VERSION ""

NS_ :

BS_:

BU_:

BO_ 3221225472 VECTOR__INDEPENDENT_SIG_MSG: 0 Vector__XXX
 SG_ New_Signal_100 : 0|8@1- (1,0) [0|0] "" Vector__XXX

BO_ 352 Shutdown_seq: 8 Vector__XXX
 SG_ shutdown_2 : 63|8@0+ (1,0) [0|0] "" Vector__XXX
 SG_ shutdown : 55|8@0+ (1,0) [0|0] "" Vector__XXX

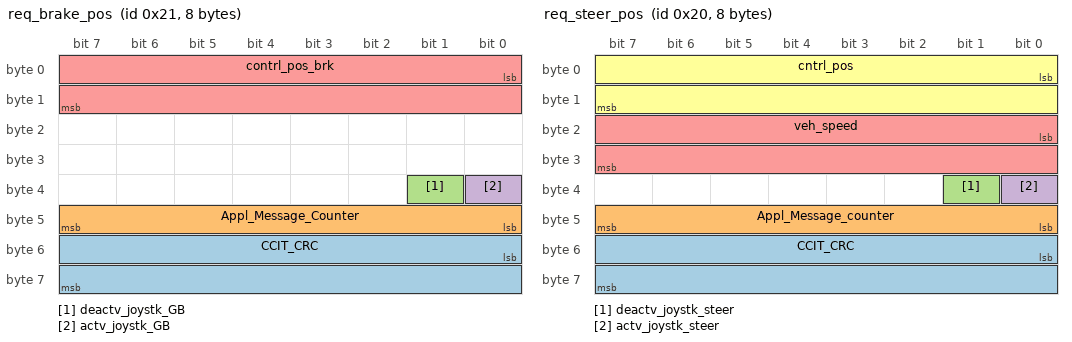
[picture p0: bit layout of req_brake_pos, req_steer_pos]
BO_ 33 req_brake_pos: 8 Vector__XXX
 SG_ CCIT_CRC : 48|16@1+ (1,0) [0|65535] "" Vector__XXX
 SG_ Appl_Message_Counter : 40|8@1+ (1,0) [0|255] "" Vector__XXX
 SG_ deactv_joystk_GB : 33|1@1+ (1,0) [0|1] "" Vector__XXX
 SG_ actv_joystk_GB : 32|1@1+ (1,0) [0|1] "" Vector__XXX
 SG_ contrl_pos_brk : 0|16@1+ (1,0) [0|65535] "" Vector__XXX

BO_ 32 req_steer_pos: 8 Vector__XXX
 SG_ CCIT_CRC : 48|16@1+ (1,0) [0|65535] "" Vector__XXX
 SG_ Appl_Message_counter : 40|8@1+ (1,0) [0|255] "" Vector__XXX
 SG_ deactv_joystk_steer : 33|1@1+ (1,0) [0|1] "" Vector__XXX
 SG_ actv_joystk_steer : 32|1@1+ (1,0) [0|1] "" Vector__XXX
 SG_ veh_speed : 16|16@1+ (1,0) [0|65535] "" Vector__XXX
 SG_ cntrl_pos : 0|16@1+ (1,0) [0|65535] "" Vector__XXX

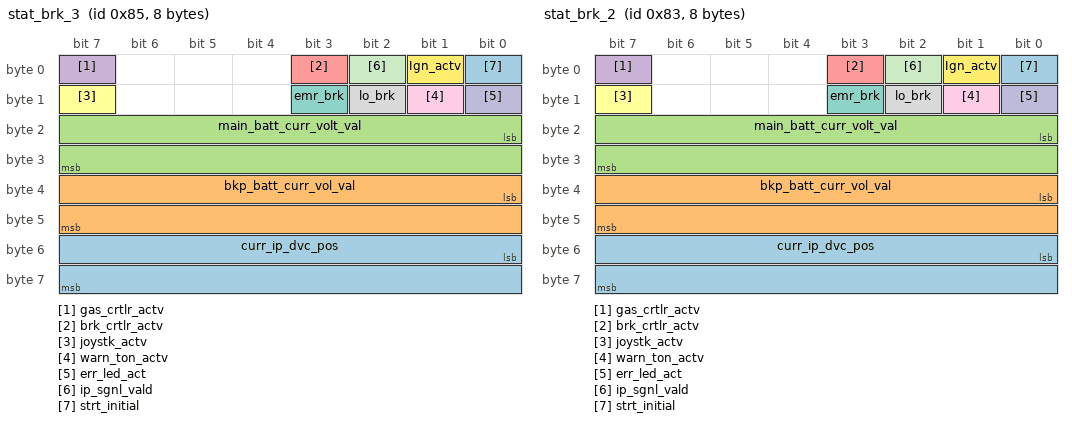
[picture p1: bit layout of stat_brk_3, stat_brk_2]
BO_ 133 stat_brk_3: 8 Vector__XXX
 SG_ curr_ip_dvc_pos : 48|16@1+ (1,0) [0|65535] "" Vector__XXX
 SG_ bkp_batt_curr_vol_val : 32|16@1+ (1,0) [0|65535] "" Vector__XXX
 SG_ main_batt_curr_volt_val : 16|16@1+ (1,0) [0|65535] "" Vector__XXX
 SG_ gas_crtlr_actv : 7|1@1+ (1,0) [0|1] "" Vector__XXX
 SG_ brk_crtlr_actv : 3|1@1+ (1,0) [0|1] "" Vector__XXX
 SG_ joystk_actv : 15|1@1+ (1,0) [0|1] "" Vector__XXX
 SG_ emr_brk : 11|1@1+ (1,0) [0|1] "" Vector__XXX
 SG_ lo_brk : 10|1@1+ (1,0) [0|1] "" Vector__XXX
 SG_ warn_ton_actv : 9|1@1+ (1,0) [0|1] "" Vector__XXX
 SG_ err_led_act : 8|1@1+ (1,0) [0|1] "" Vector__XXX
 SG_ ip_sgnl_vald : 2|1@1+ (1,0) [0|1] "" Vector__XXX
 SG_ Ign_actv : 1|1@1+ (1,0) [0|1] "" Vector__XXX
 SG_ strt_initial : 0|1@1+ (1,0) [0|1] "" Vector__XXX

BO_ 131 stat_brk_2: 8 Vector__XXX
 SG_ curr_ip_dvc_pos : 48|16@1+ (1,0) [0|65535] "" Vector__XXX
 SG_ bkp_batt_curr_vol_val : 32|16@1+ (1,0) [0|65535] "" Vector__XXX
 SG_ main_batt_curr_volt_val : 16|16@1+ (1,0) [0|65535] "" Vector__XXX
 SG_ gas_crtlr_actv : 7|1@1+ (1,0) [0|1] "" Vector__XXX
 SG_ brk_crtlr_actv : 3|1@1+ (1,0) [0|1] "" Vector__XXX
 SG_ joystk_actv : 15|1@1+ (1,0) [0|1] "" Vector__XXX
 SG_ emr_brk : 11|1@1+ (1,0) [0|1] "" Vector__XXX
 SG_ lo_brk : 10|1@1+ (1,0) [0|1] "" Vector__XXX
 SG_ warn_ton_actv : 9|1@1+ (1,0) [0|1] "" Vector__XXX
 SG_ err_led_act : 8|1@1+ (1,0) [0|1] "" Vector__XXX
 SG_ ip_sgnl_vald : 2|1@1+ (1,0) [0|1] "" Vector__XXX
 SG_ Ign_actv : 1|1@1+ (1,0) [0|1] "" Vector__XXX
 SG_ strt_initial : 0|1@1+ (1,0) [0|1] "" Vector__XXX

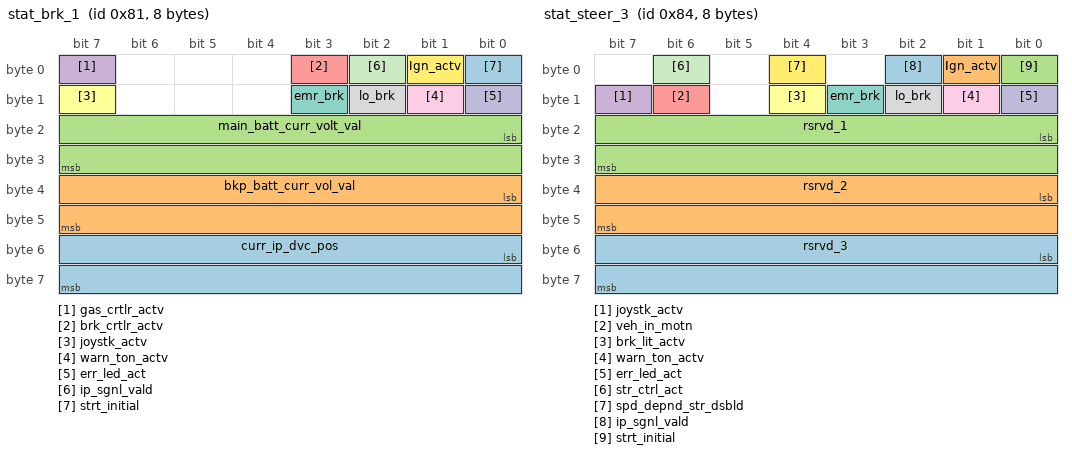
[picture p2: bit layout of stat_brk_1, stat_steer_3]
BO_ 129 stat_brk_1: 8 Vector__XXX
 SG_ curr_ip_dvc_pos : 48|16@1+ (1,0) [0|65535] "" Vector__XXX
 SG_ bkp_batt_curr_vol_val : 32|16@1+ (1,0) [0|65535] "" Vector__XXX
 SG_ main_batt_curr_volt_val : 16|16@1+ (1,0) [0|65535] "" Vector__XXX
 SG_ gas_crtlr_actv : 7|1@1+ (1,0) [0|1] "" Vector__XXX
 SG_ brk_crtlr_actv : 3|1@1+ (1,0) [0|1] "" Vector__XXX
 SG_ joystk_actv : 15|1@1+ (1,0) [0|1] "" Vector__XXX
 SG_ emr_brk : 11|1@1+ (1,0) [0|1] "" Vector__XXX
 SG_ lo_brk : 10|1@1+ (1,0) [0|1] "" Vector__XXX
 SG_ warn_ton_actv : 9|1@1+ (1,0) [0|1] "" Vector__XXX
 SG_ err_led_act : 8|1@1+ (1,0) [0|1] "" Vector__XXX
 SG_ ip_sgnl_vald : 2|1@1+ (1,0) [0|1] "" Vector__XXX
 SG_ Ign_actv : 1|1@1+ (1,0) [0|1] "" Vector__XXX
 SG_ strt_initial : 0|1@1+ (1,0) [0|1] "" Vector__XXX

BO_ 132 stat_steer_3: 8 Vector__XXX
 SG_ rsrvd_3 : 48|16@1+ (1,0) [0|65535] "" Vector__XXX
 SG_ rsrvd_2 : 32|16@1+ (1,0) [0|65535] "" Vector__XXX
 SG_ rsrvd_1 : 16|16@1+ (1,0) [0|65535] "" Vector__XXX
 SG_ joystk_actv : 15|1@1+ (1,0) [0|1] "" Vector__XXX
 SG_ veh_in_motn : 14|1@1+ (1,0) [0|1] "" Vector__XXX
 SG_ brk_lit_actv : 12|1@1+ (1,0) [0|1] "" Vector__XXX
 SG_ emr_brk : 11|1@1+ (1,0) [0|1] "" Vector__XXX
 SG_ lo_brk : 10|1@1+ (1,0) [0|1] "" Vector__XXX
 SG_ warn_ton_actv : 9|1@1+ (1,0) [0|1] "" Vector__XXX
 SG_ err_led_act : 8|1@1+ (1,0) [0|1] "" Vector__XXX
 SG_ str_ctrl_act : 6|1@1+ (1,0) [0|1] "" Vector__XXX
 SG_ spd_depnd_str_dsbld : 4|1@1+ (1,0) [0|1] "" Vector__XXX
 SG_ ip_sgnl_vald : 2|1@1+ (1,0) [0|1] "" Vector__XXX
 SG_ Ign_actv : 1|1@1+ (1,0) [0|1] "" Vector__XXX
 SG_ strt_initial : 0|1@1+ (1,0) [0|1] "" Vector__XXX

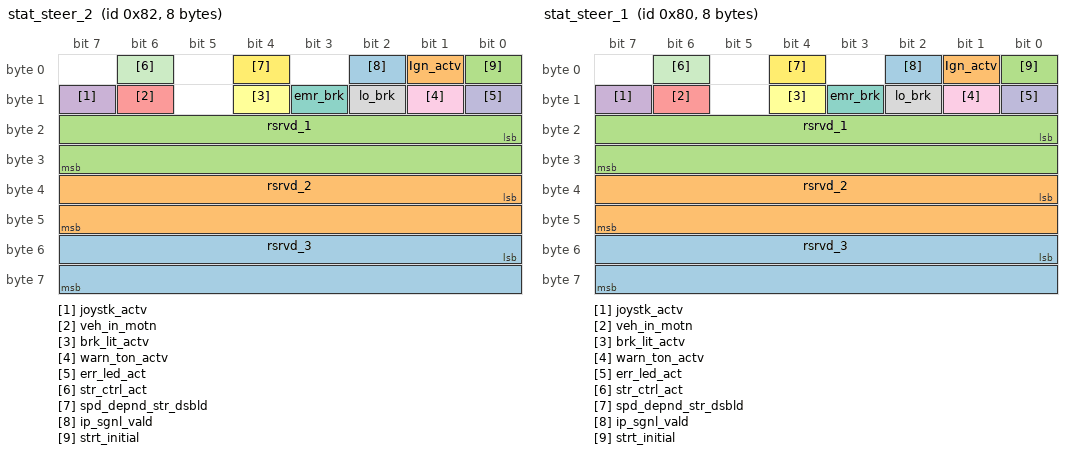
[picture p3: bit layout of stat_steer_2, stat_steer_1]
BO_ 130 stat_steer_2: 8 Vector__XXX
 SG_ rsrvd_3 : 48|16@1+ (1,0) [0|65535] "" Vector__XXX
 SG_ rsrvd_2 : 32|16@1+ (1,0) [0|65535] "" Vector__XXX
 SG_ rsrvd_1 : 16|16@1+ (1,0) [0|65535] "" Vector__XXX
 SG_ joystk_actv : 15|1@1+ (1,0) [0|1] "" Vector__XXX
 SG_ veh_in_motn : 14|1@1+ (1,0) [0|1] "" Vector__XXX
 SG_ brk_lit_actv : 12|1@1+ (1,0) [0|1] "" Vector__XXX
 SG_ emr_brk : 11|1@1+ (1,0) [0|1] "" Vector__XXX
 SG_ lo_brk : 10|1@1+ (1,0) [0|1] "" Vector__XXX
 SG_ warn_ton_actv : 9|1@1+ (1,0) [0|1] "" Vector__XXX
 SG_ err_led_act : 8|1@1+ (1,0) [0|1] "" Vector__XXX
 SG_ str_ctrl_act : 6|1@1+ (1,0) [0|1] "" Vector__XXX
 SG_ spd_depnd_str_dsbld : 4|1@1+ (1,0) [0|1] "" Vector__XXX
 SG_ ip_sgnl_vald : 2|1@1+ (1,0) [0|1] "" Vector__XXX
 SG_ Ign_actv : 1|1@1+ (1,0) [0|1] "" Vector__XXX
 SG_ strt_initial : 0|1@1+ (1,0) [0|1] "" Vector__XXX

BO_ 128 stat_steer_1: 8 Vector__XXX
 SG_ rsrvd_3 : 48|16@1+ (1,0) [0|65535] "" Vector__XXX
 SG_ rsrvd_2 : 32|16@1+ (1,0) [0|65535] "" Vector__XXX
 SG_ rsrvd_1 : 16|16@1+ (1,0) [0|65535] "" Vector__XXX
 SG_ joystk_actv : 15|1@1+ (1,0) [0|1] "" Vector__XXX
 SG_ veh_in_motn : 14|1@1+ (1,0) [0|1] "" Vector__XXX
 SG_ brk_lit_actv : 12|1@1+ (1,0) [0|1] "" Vector__XXX
 SG_ emr_brk : 11|1@1+ (1,0) [0|1] "" Vector__XXX
 SG_ lo_brk : 10|1@1+ (1,0) [0|1] "" Vector__XXX
 SG_ warn_ton_actv : 9|1@1+ (1,0) [0|1] "" Vector__XXX
 SG_ err_led_act : 8|1@1+ (1,0) [0|1] "" Vector__XXX
 SG_ str_ctrl_act : 6|1@1+ (1,0) [0|1] "" Vector__XXX
 SG_ spd_depnd_str_dsbld : 4|1@1+ (1,0) [0|1] "" Vector__XXX
 SG_ ip_sgnl_vald : 2|1@1+ (1,0) [0|1] "" Vector__XXX
 SG_ Ign_actv : 1|1@1+ (1,0) [0|1] "" Vector__XXX
 SG_ strt_initial : 0|1@1+ (1,0) [0|1] "" Vector__XXX

BO_ 101 act_err_brake_3: 8 Vector__XXX
 SG_ crtcl_err_recognzd : 62|1@1+ (1,0) [0|1] "" Vector__XXX
 SG_ err_CAN_2 : 58|1@1+ (1,0) [0|1] "" Vector__XXX
 SG_ err_CAN_1 : 57|1@1+ (1,0) [0|1] "" Vector__XXX
 SG_ ovrld_mtr_pwr : 51|1@1+ (1,0) [0|1] "" Vector__XXX
 SG_ runtm_err : 50|1@1+ (1,0) [0|1] "" Vector__XXX
 SG_ err_memo_100_pcnt_full : 44|1@1+ (1,0) [0|1] "" Vector__XXX
 SG_ err_memo_80_pcnt_full : 43|1@1+ (1,0) [0|1] "" Vector__XXX
 SG_ ctrlr_temp_to_hi : 42|1@1+ (1,0) [0|1] "" Vector__XXX
 SG_ psn_sen_srv_mtr_implausible : 39|1@1+ (1,0) [0|1] "" Vector__XXX
 SG_ RESET_whl_optg : 38|1@1+ (1,0) [0|1] "" Vector__XXX
 SG_ err_ctrl_val_2 : 37|1@1+ (1,0) [0|1] "" Vector__XXX
 SG_ err_ctrl_val_1 : 36|1@1+ (1,0) [0|1] "" Vector__XXX
 SG_ err_ngv_voltg_pwr_supp_3 : 35|1@1+ (1,0) [0|1] "" Vector__XXX
 SG_ err_ngv_voltg_pwr_supp_2 : 34|1@1+ (1,0) [0|1] "" Vector__XXX
 SG_ err_ngv_voltg_pwr_supp_1 : 33|1@1+ (1,0) [0|1] "" Vector__XXX
 SG_ err_3p3V_pwr_supp_2 : 32|1@1+ (1,0) [0|1] "" Vector__XXX
 SG_ err_3p3V_pwr_supp_1 : 31|1@1+ (1,0) [0|1] "" Vector__XXX
 SG_ err_5V_pwr_supp_3 : 30|1@1+ (1,0) [0|1] "" Vector__XXX
 SG_ err_5V_pwr_supp_2 : 29|1@1+ (1,0) [0|1] "" Vector__XXX
 SG_ err_5V_pwr_supp_1 : 28|1@1+ (1,0) [0|1] "" Vector__XXX
 SG_ H_brdg_3_fail : 27|1@1+ (1,0) [0|1] "" Vector__XXX
 SG_ H_brdg_2_fail : 26|1@1+ (1,0) [0|1] "" Vector__XXX
 SG_ H_brdg_1_fail : 25|1@1+ (1,0) [0|1] "" Vector__XXX
 SG_ err_srv_mtr_pos_sen_3 : 23|1@1+ (1,0) [0|1] "" Vector__XXX
 SG_ err_srv_mtr_2_STR_pwr_drn : 22|1@1+ (1,0) [0|1] "" Vector__XXX
 SG_ err_srv_mtr_1_STR_pwr_drn : 21|1@1+ (1,0) [0|1] "" Vector__XXX
 SG_ RAM_Chk_fail : 20|1@1+ (1,0) [0|1] "" Vector__XXX
 SG_ flsh_CRC_fail : 19|1@1+ (1,0) [0|1] "" Vector__XXX
 SG_ Ctrlr_temp_crit_low : 12|1@1+ (1,0) [0|1] "" Vector__XXX
 SG_ Ctrlr_temp_crit_hi : 11|1@1+ (1,0) [0|1] "" Vector__XXX
 SG_ err_srv_mtr_2_GB_pwr_drn : 10|1@1+ (1,0) [0|1] "" Vector__XXX
 SG_ err_srv_mtr_1_GB_pwr_drn : 9|1@1+ (1,0) [0|1] "" Vector__XXX
 SG_ Vol_bkp_batt_lo : 8|1@1+ (1,0) [0|1] "" Vector__XXX
 SG_ Vol_bkp_batt_hi : 7|1@1+ (1,0) [0|1] "" Vector__XXX
 SG_ Vol_main_batt_lo : 6|1@1+ (1,0) [0|1] "" Vector__XXX
 SG_ Vol_main_batt_hi : 5|1@1+ (1,0) [0|1] "" Vector__XXX
 SG_ err_srv_mtr_pos_sen_2 : 4|1@1+ (1,0) [0|1] "" Vector__XXX
 SG_ err_srv_mtr_pos_sen_1 : 3|1@1+ (1,0) [0|1] "" Vector__XXX
 SG_ ip_dvc_err_sen_3 : 2|1@1+ (1,0) [0|1] "" Vector__XXX
 SG_ ip_dvc_err_sen_2 : 1|1@1+ (1,0) [0|1] "" Vector__XXX
 SG_ ip_dvc_err_sen_1 : 0|1@1+ (1,0) [0|1] "" Vector__XXX

BO_ 99 act_err_brake_2: 8 Vector__XXX
 SG_ crtcl_err_recognzd : 62|1@1+ (1,0) [0|1] "" Vector__XXX
 SG_ err_CAN_2 : 58|1@1+ (1,0) [0|1] "" Vector__XXX
 SG_ err_CAN_1 : 57|1@1+ (1,0) [0|1] "" Vector__XXX
 SG_ ovrld_mtr_pwr : 51|1@1+ (1,0) [0|1] "" Vector__XXX
 SG_ runtm_err : 50|1@1+ (1,0) [0|1] "" Vector__XXX
 SG_ err_memo_100_pcnt_full : 44|1@1+ (1,0) [0|1] "" Vector__XXX
 SG_ err_memo_80_pcnt_full : 43|1@1+ (1,0) [0|1] "" Vector__XXX
 SG_ ctrlr_temp_to_hi : 42|1@1+ (1,0) [0|1] "" Vector__XXX
 SG_ psn_sen_srv_mtr_implausible : 39|1@1+ (1,0) [0|1] "" Vector__XXX
 SG_ RESET_whl_optg : 38|1@1+ (1,0) [0|1] "" Vector__XXX
 SG_ err_ctrl_val_2 : 37|1@1+ (1,0) [0|1] "" Vector__XXX
 SG_ err_ctrl_val_1 : 36|1@1+ (1,0) [0|1] "" Vector__XXX
 SG_ err_ngv_voltg_pwr_supp_3 : 35|1@1+ (1,0) [0|1] "" Vector__XXX
 SG_ err_ngv_voltg_pwr_supp_2 : 34|1@1+ (1,0) [0|1] "" Vector__XXX
 SG_ err_ngv_voltg_pwr_supp_1 : 33|1@1+ (1,0) [0|1] "" Vector__XXX
 SG_ err_3p3V_pwr_supp_2 : 32|1@1+ (1,0) [0|1] "" Vector__XXX
 SG_ err_3p3V_pwr_supp_1 : 31|1@1+ (1,0) [0|1] "" Vector__XXX
 SG_ err_5V_pwr_supp_3 : 30|1@1+ (1,0) [0|1] "" Vector__XXX
 SG_ err_5V_pwr_supp_2 : 29|1@1+ (1,0) [0|1] "" Vector__XXX
 SG_ err_5V_pwr_supp_1 : 28|1@1+ (1,0) [0|1] "" Vector__XXX
 SG_ H_brdg_3_fail : 27|1@1+ (1,0) [0|1] "" Vector__XXX
 SG_ H_brdg_2_fail : 26|1@1+ (1,0) [0|1] "" Vector__XXX
 SG_ H_brdg_1_fail : 25|1@1+ (1,0) [0|1] "" Vector__XXX
 SG_ err_srv_mtr_pos_sen_3 : 23|1@1+ (1,0) [0|1] "" Vector__XXX
 SG_ err_srv_mtr_2_STR_pwr_drn : 22|1@1+ (1,0) [0|1] "" Vector__XXX
 SG_ err_srv_mtr_1_STR_pwr_drn : 21|1@1+ (1,0) [0|1] "" Vector__XXX
 SG_ RAM_Chk_fail : 20|1@1+ (1,0) [0|1] "" Vector__XXX
 SG_ flsh_CRC_fail : 19|1@1+ (1,0) [0|1] "" Vector__XXX
 SG_ Ctrlr_temp_crit_low : 12|1@1+ (1,0) [0|1] "" Vector__XXX
 SG_ Ctrlr_temp_crit_hi : 11|1@1+ (1,0) [0|1] "" Vector__XXX
 SG_ err_srv_mtr_2_GB_pwr_drn : 10|1@1+ (1,0) [0|1] "" Vector__XXX
 SG_ err_srv_mtr_1_GB_pwr_drn : 9|1@1+ (1,0) [0|1] "" Vector__XXX
 SG_ Vol_bkp_batt_lo : 8|1@1+ (1,0) [0|1] "" Vector__XXX
 SG_ Vol_bkp_batt_hi : 7|1@1+ (1,0) [0|1] "" Vector__XXX
 SG_ Vol_main_batt_lo : 6|1@1+ (1,0) [0|1] "" Vector__XXX
 SG_ Vol_main_batt_hi : 5|1@1+ (1,0) [0|1] "" Vector__XXX
 SG_ err_srv_mtr_pos_sen_2 : 4|1@1+ (1,0) [0|1] "" Vector__XXX
 SG_ err_srv_mtr_pos_sen_1 : 3|1@1+ (1,0) [0|1] "" Vector__XXX
 SG_ ip_dvc_err_sen_3 : 2|1@1+ (1,0) [0|1] "" Vector__XXX
 SG_ ip_dvc_err_sen_2 : 1|1@1+ (1,0) [0|1] "" Vector__XXX
 SG_ ip_dvc_err_sen_1 : 0|1@1+ (1,0) [0|1] "" Vector__XXX

BO_ 100 act_err_steer_3: 8 Vector__XXX
 SG_ crtcl_err_recognzd : 62|1@1+ (1,0) [0|1] "" Vector__XXX
 SG_ err_CAN_2 : 58|1@1+ (1,0) [0|1] "" Vector__XXX
 SG_ err_CAN_1 : 57|1@1+ (1,0) [0|1] "" Vector__XXX
 SG_ ovrld_mtr_pwr : 51|1@1+ (1,0) [0|1] "" Vector__XXX
 SG_ runtm_err : 50|1@1+ (1,0) [0|1] "" Vector__XXX
 SG_ err_memo_100_pcnt_full : 44|1@1+ (1,0) [0|1] "" Vector__XXX
 SG_ err_memo_80_pcnt_full : 43|1@1+ (1,0) [0|1] "" Vector__XXX
 SG_ ctrlr_temp_to_hi : 42|1@1+ (1,0) [0|1] "" Vector__XXX
 SG_ psn_sen_srv_mtr_implausible : 39|1@1+ (1,0) [0|1] "" Vector__XXX
 SG_ RESET_whl_optg : 38|1@1+ (1,0) [0|1] "" Vector__XXX
 SG_ err_ctrl_val_2 : 37|1@1+ (1,0) [0|1] "" Vector__XXX
 SG_ err_ctrl_val_1 : 36|1@1+ (1,0) [0|1] "" Vector__XXX
 SG_ err_ngv_voltg_pwr_supp_3 : 35|1@1+ (1,0) [0|1] "" Vector__XXX
 SG_ err_ngv_voltg_pwr_supp_2 : 34|1@1+ (1,0) [0|1] "" Vector__XXX
 SG_ err_ngv_voltg_pwr_supp_1 : 33|1@1+ (1,0) [0|1] "" Vector__XXX
 SG_ err_3p3V_pwr_supp_2 : 32|1@1+ (1,0) [0|1] "" Vector__XXX
 SG_ err_3p3V_pwr_supp_1 : 31|1@1+ (1,0) [0|1] "" Vector__XXX
 SG_ err_5V_pwr_supp_3 : 30|1@1+ (1,0) [0|1] "" Vector__XXX
 SG_ err_5V_pwr_supp_2 : 29|1@1+ (1,0) [0|1] "" Vector__XXX
 SG_ err_5V_pwr_supp_1 : 28|1@1+ (1,0) [0|1] "" Vector__XXX
 SG_ H_brdg_3_fail : 27|1@1+ (1,0) [0|1] "" Vector__XXX
 SG_ H_brdg_2_fail : 26|1@1+ (1,0) [0|1] "" Vector__XXX
 SG_ H_brdg_1_fail : 25|1@1+ (1,0) [0|1] "" Vector__XXX
 SG_ err_srv_mtr_pos_sen_3 : 23|1@1+ (1,0) [0|1] "" Vector__XXX
 SG_ err_srv_mtr_2_STR_pwr_drn : 22|1@1+ (1,0) [0|1] "" Vector__XXX
 SG_ err_srv_mtr_1_STR_pwr_drn : 21|1@1+ (1,0) [0|1] "" Vector__XXX
 SG_ RAM_Chk_fail : 20|1@1+ (1,0) [0|1] "" Vector__XXX
 SG_ flsh_CRC_fail : 19|1@1+ (1,0) [0|1] "" Vector__XXX
 SG_ Ctrlr_temp_crit_low : 12|1@1+ (1,0) [0|1] "" Vector__XXX
 SG_ Ctrlr_temp_crit_hi : 11|1@1+ (1,0) [0|1] "" Vector__XXX
 SG_ err_srv_mtr_2_GB_pwr_drn : 10|1@1+ (1,0) [0|1] "" Vector__XXX
 SG_ err_srv_mtr_1_GB_pwr_drn : 9|1@1+ (1,0) [0|1] "" Vector__XXX
 SG_ Vol_bkp_batt_lo : 8|1@1+ (1,0) [0|1] "" Vector__XXX
 SG_ Vol_bkp_batt_hi : 7|1@1+ (1,0) [0|1] "" Vector__XXX
 SG_ Vol_main_batt_lo : 6|1@1+ (1,0) [0|1] "" Vector__XXX
 SG_ Vol_main_batt_hi : 5|1@1+ (1,0) [0|1] "" Vector__XXX
 SG_ err_srv_mtr_pos_sen_2 : 4|1@1+ (1,0) [0|1] "" Vector__XXX
 SG_ err_srv_mtr_pos_sen_1 : 3|1@1+ (1,0) [0|1] "" Vector__XXX
 SG_ ip_dvc_err_sen_3 : 2|1@1+ (1,0) [0|1] "" Vector__XXX
 SG_ ip_dvc_err_sen_2 : 1|1@1+ (1,0) [0|1] "" Vector__XXX
 SG_ ip_dvc_err_sen_1 : 0|1@1+ (1,0) [0|1] "" Vector__XXX

BO_ 98 act_err_steer_2: 8 Vector__XXX
 SG_ crtcl_err_recognzd : 62|1@1+ (1,0) [0|1] "" Vector__XXX
 SG_ err_CAN_2 : 58|1@1+ (1,0) [0|1] "" Vector__XXX
 SG_ err_CAN_1 : 57|1@1+ (1,0) [0|1] "" Vector__XXX
 SG_ ovrld_mtr_pwr : 51|1@1+ (1,0) [0|1] "" Vector__XXX
 SG_ runtm_err : 50|1@1+ (1,0) [0|1] "" Vector__XXX
 SG_ err_memo_100_pcnt_full : 44|1@1+ (1,0) [0|1] "" Vector__XXX
 SG_ err_memo_80_pcnt_full : 43|1@1+ (1,0) [0|1] "" Vector__XXX
 SG_ ctrlr_temp_to_hi : 42|1@1+ (1,0) [0|1] "" Vector__XXX
 SG_ psn_sen_srv_mtr_implausible : 39|1@1+ (1,0) [0|1] "" Vector__XXX
 SG_ RESET_whl_optg : 38|1@1+ (1,0) [0|1] "" Vector__XXX
 SG_ err_ctrl_val_2 : 37|1@1+ (1,0) [0|1] "" Vector__XXX
 SG_ err_ctrl_val_1 : 36|1@1+ (1,0) [0|1] "" Vector__XXX
 SG_ err_ngv_voltg_pwr_supp_3 : 35|1@1+ (1,0) [0|1] "" Vector__XXX
 SG_ err_ngv_voltg_pwr_supp_2 : 34|1@1+ (1,0) [0|1] "" Vector__XXX
 SG_ err_ngv_voltg_pwr_supp_1 : 33|1@1+ (1,0) [0|1] "" Vector__XXX
 SG_ err_3p3V_pwr_supp_2 : 32|1@1+ (1,0) [0|1] "" Vector__XXX
 SG_ err_3p3V_pwr_supp_1 : 31|1@1+ (1,0) [0|1] "" Vector__XXX
 SG_ err_5V_pwr_supp_3 : 30|1@1+ (1,0) [0|1] "" Vector__XXX
 SG_ err_5V_pwr_supp_2 : 29|1@1+ (1,0) [0|1] "" Vector__XXX
 SG_ err_5V_pwr_supp_1 : 28|1@1+ (1,0) [0|1] "" Vector__XXX
 SG_ H_brdg_3_fail : 27|1@1+ (1,0) [0|1] "" Vector__XXX
 SG_ H_brdg_2_fail : 26|1@1+ (1,0) [0|1] "" Vector__XXX
 SG_ H_brdg_1_fail : 25|1@1+ (1,0) [0|1] "" Vector__XXX
 SG_ err_srv_mtr_pos_sen_3 : 23|1@1+ (1,0) [0|1] "" Vector__XXX
 SG_ err_srv_mtr_2_STR_pwr_drn : 22|1@1+ (1,0) [0|1] "" Vector__XXX
 SG_ err_srv_mtr_1_STR_pwr_drn : 21|1@1+ (1,0) [0|1] "" Vector__XXX
 SG_ RAM_Chk_fail : 20|1@1+ (1,0) [0|1] "" Vector__XXX
 SG_ flsh_CRC_fail : 19|1@1+ (1,0) [0|1] "" Vector__XXX
 SG_ Ctrlr_temp_crit_low : 12|1@1+ (1,0) [0|1] "" Vector__XXX
 SG_ Ctrlr_temp_crit_hi : 11|1@1+ (1,0) [0|1] "" Vector__XXX
 SG_ err_srv_mtr_2_GB_pwr_drn : 10|1@1+ (1,0) [0|1] "" Vector__XXX
 SG_ err_srv_mtr_1_GB_pwr_drn : 9|1@1+ (1,0) [0|1] "" Vector__XXX
 SG_ Vol_bkp_batt_lo : 8|1@1+ (1,0) [0|1] "" Vector__XXX
 SG_ Vol_bkp_batt_hi : 7|1@1+ (1,0) [0|1] "" Vector__XXX
 SG_ Vol_main_batt_lo : 6|1@1+ (1,0) [0|1] "" Vector__XXX
 SG_ Vol_main_batt_hi : 5|1@1+ (1,0) [0|1] "" Vector__XXX
 SG_ err_srv_mtr_pos_sen_2 : 4|1@1+ (1,0) [0|1] "" Vector__XXX
 SG_ err_srv_mtr_pos_sen_1 : 3|1@1+ (1,0) [0|1] "" Vector__XXX
 SG_ ip_dvc_err_sen_3 : 2|1@1+ (1,0) [0|1] "" Vector__XXX
 SG_ ip_dvc_err_sen_2 : 1|1@1+ (1,0) [0|1] "" Vector__XXX
 SG_ ip_dvc_err_sen_1 : 0|1@1+ (1,0) [0|1] "" Vector__XXX

BO_ 97 act_err_brake_1: 8 Vector__XXX
 SG_ crtcl_err_recognzd : 62|1@1+ (1,0) [0|1] "" Vector__XXX
 SG_ err_CAN_2 : 58|1@1+ (1,0) [0|1] "" Vector__XXX
 SG_ err_CAN_1 : 57|1@1+ (1,0) [0|1] "" Vector__XXX
 SG_ ovrld_mtr_pwr : 51|1@1+ (1,0) [0|1] "" Vector__XXX
 SG_ runtm_err : 50|1@1+ (1,0) [0|1] "" Vector__XXX
 SG_ err_memo_100_pcnt_full : 44|1@1+ (1,0) [0|1] "" Vector__XXX
 SG_ err_memo_80_pcnt_full : 43|1@1+ (1,0) [0|1] "" Vector__XXX
 SG_ ctrlr_temp_to_hi : 42|1@1+ (1,0) [0|1] "" Vector__XXX
 SG_ psn_sen_srv_mtr_implausible : 39|1@1+ (1,0) [0|1] "" Vector__XXX
 SG_ RESET_whl_optg : 38|1@1+ (1,0) [0|1] "" Vector__XXX
 SG_ err_ctrl_val_2 : 37|1@1+ (1,0) [0|1] "" Vector__XXX
 SG_ err_ctrl_val_1 : 36|1@1+ (1,0) [0|1] "" Vector__XXX
 SG_ err_ngv_voltg_pwr_supp_3 : 35|1@1+ (1,0) [0|1] "" Vector__XXX
 SG_ err_ngv_voltg_pwr_supp_2 : 34|1@1+ (1,0) [0|1] "" Vector__XXX
 SG_ err_ngv_voltg_pwr_supp_1 : 33|1@1+ (1,0) [0|1] "" Vector__XXX
 SG_ err_3p3V_pwr_supp_2 : 32|1@1+ (1,0) [0|1] "" Vector__XXX
 SG_ err_3p3V_pwr_supp_1 : 31|1@1+ (1,0) [0|1] "" Vector__XXX
 SG_ err_5V_pwr_supp_3 : 30|1@1+ (1,0) [0|1] "" Vector__XXX
 SG_ err_5V_pwr_supp_2 : 29|1@1+ (1,0) [0|1] "" Vector__XXX
 SG_ err_5V_pwr_supp_1 : 28|1@1+ (1,0) [0|1] "" Vector__XXX
 SG_ H_brdg_3_fail : 27|1@1+ (1,0) [0|1] "" Vector__XXX
 SG_ H_brdg_2_fail : 26|1@1+ (1,0) [0|1] "" Vector__XXX
 SG_ H_brdg_1_fail : 25|1@1+ (1,0) [0|1] "" Vector__XXX
 SG_ err_srv_mtr_pos_sen_3 : 23|1@1+ (1,0) [0|1] "" Vector__XXX
 SG_ err_srv_mtr_2_STR_pwr_drn : 22|1@1+ (1,0) [0|1] "" Vector__XXX
 SG_ err_srv_mtr_1_STR_pwr_drn : 21|1@1+ (1,0) [0|1] "" Vector__XXX
 SG_ RAM_Chk_fail : 20|1@1+ (1,0) [0|1] "" Vector__XXX
 SG_ flsh_CRC_fail : 19|1@1+ (1,0) [0|1] "" Vector__XXX
 SG_ Ctrlr_temp_crit_low : 12|1@1+ (1,0) [0|1] "" Vector__XXX
 SG_ Ctrlr_temp_crit_hi : 11|1@1+ (1,0) [0|1] "" Vector__XXX
 SG_ err_srv_mtr_2_GB_pwr_drn : 10|1@1+ (1,0) [0|1] "" Vector__XXX
 SG_ err_srv_mtr_1_GB_pwr_drn : 9|1@1+ (1,0) [0|1] "" Vector__XXX
 SG_ Vol_bkp_batt_lo : 8|1@1+ (1,0) [0|1] "" Vector__XXX
 SG_ Vol_bkp_batt_hi : 7|1@1+ (1,0) [0|1] "" Vector__XXX
 SG_ Vol_main_batt_lo : 6|1@1+ (1,0) [0|1] "" Vector__XXX
 SG_ Vol_main_batt_hi : 5|1@1+ (1,0) [0|1] "" Vector__XXX
 SG_ err_srv_mtr_pos_sen_2 : 4|1@1+ (1,0) [0|1] "" Vector__XXX
 SG_ err_srv_mtr_pos_sen_1 : 3|1@1+ (1,0) [0|1] "" Vector__XXX
 SG_ ip_dvc_err_sen_3 : 2|1@1+ (1,0) [0|1] "" Vector__XXX
 SG_ ip_dvc_err_sen_2 : 1|1@1+ (1,0) [0|1] "" Vector__XXX
 SG_ ip_dvc_err_sen_1 : 0|1@1+ (1,0) [0|1] "" Vector__XXX

BO_ 96 act_err_steer_1: 8 Vector__XXX
 SG_ crtcl_err_recognzd : 62|1@1+ (1,0) [0|1] "" Vector__XXX
 SG_ err_CAN_2 : 58|1@1+ (1,0) [0|1] "" Vector__XXX
 SG_ err_CAN_1 : 57|1@1+ (1,0) [0|1] "" Vector__XXX
 SG_ ovrld_mtr_pwr : 51|1@1+ (1,0) [0|1] "" Vector__XXX
 SG_ runtm_err : 50|1@1+ (1,0) [0|1] "" Vector__XXX
 SG_ err_memo_100_pcnt_full : 44|1@1+ (1,0) [0|1] "" Vector__XXX
 SG_ err_memo_80_pcnt_full : 43|1@1+ (1,0) [0|1] "" Vector__XXX
 SG_ ctrlr_temp_to_hi : 42|1@1+ (1,0) [0|1] "" Vector__XXX
 SG_ psn_sen_srv_mtr_implausible : 39|1@1+ (1,0) [0|1] "" Vector__XXX
 SG_ RESET_whl_optg : 38|1@1+ (1,0) [0|1] "" Vector__XXX
 SG_ err_ctrl_val_2 : 37|1@1+ (1,0) [0|1] "" Vector__XXX
 SG_ err_ctrl_val_1 : 36|1@1+ (1,0) [0|1] "" Vector__XXX
 SG_ err_ngv_voltg_pwr_supp_3 : 35|1@1+ (1,0) [0|1] "" Vector__XXX
 SG_ err_ngv_voltg_pwr_supp_2 : 34|1@1+ (1,0) [0|1] "" Vector__XXX
 SG_ err_ngv_voltg_pwr_supp_1 : 33|1@1+ (1,0) [0|1] "" Vector__XXX
 SG_ err_3p3V_pwr_supp_2 : 32|1@1+ (1,0) [0|1] "" Vector__XXX
 SG_ err_3p3V_pwr_supp_1 : 31|1@1+ (1,0) [0|1] "" Vector__XXX
 SG_ err_5V_pwr_supp_3 : 30|1@1+ (1,0) [0|1] "" Vector__XXX
 SG_ err_5V_pwr_supp_2 : 29|1@1+ (1,0) [0|1] "" Vector__XXX
 SG_ err_5V_pwr_supp_1 : 28|1@1+ (1,0) [0|1] "" Vector__XXX
 SG_ H_brdg_3_fail : 27|1@1+ (1,0) [0|1] "" Vector__XXX
 SG_ H_brdg_2_fail : 26|1@1+ (1,0) [0|1] "" Vector__XXX
 SG_ H_brdg_1_fail : 25|1@1+ (1,0) [0|1] "" Vector__XXX
 SG_ err_srv_mtr_pos_sen_3 : 23|1@1+ (1,0) [0|1] "" Vector__XXX
 SG_ err_srv_mtr_2_STR_pwr_drn : 22|1@1+ (1,0) [0|1] "" Vector__XXX
 SG_ err_srv_mtr_1_STR_pwr_drn : 21|1@1+ (1,0) [0|1] "" Vector__XXX
 SG_ RAM_Chk_fail : 20|1@1+ (1,0) [0|1] "" Vector__XXX
 SG_ flsh_CRC_fail : 19|1@1+ (1,0) [0|1] "" Vector__XXX
 SG_ Ctrlr_temp_crit_low : 12|1@1+ (1,0) [0|1] "" Vector__XXX
 SG_ Ctrlr_temp_crit_hi : 11|1@1+ (1,0) [0|1] "" Vector__XXX
 SG_ err_srv_mtr_2_GB_pwr_drn : 10|1@1+ (1,0) [0|1] "" Vector__XXX
 SG_ err_srv_mtr_1_GB_pwr_drn : 9|1@1+ (1,0) [0|1] "" Vector__XXX
 SG_ Vol_bkp_batt_lo : 8|1@1+ (1,0) [0|1] "" Vector__XXX
 SG_ Vol_bkp_batt_hi : 7|1@1+ (1,0) [0|1] "" Vector__XXX
 SG_ Vol_main_batt_lo : 6|1@1+ (1,0) [0|1] "" Vector__XXX
 SG_ Vol_main_batt_hi : 5|1@1+ (1,0) [0|1] "" Vector__XXX
 SG_ err_srv_mtr_pos_sen_2 : 4|1@1+ (1,0) [0|1] "" Vector__XXX
 SG_ err_srv_mtr_pos_sen_1 : 3|1@1+ (1,0) [0|1] "" Vector__XXX
 SG_ ip_dvc_err_sen_3 : 2|1@1+ (1,0) [0|1] "" Vector__XXX
 SG_ ip_dvc_err_sen_2 : 1|1@1+ (1,0) [0|1] "" Vector__XXX
 SG_ ip_dvc_err_sen_1 : 0|1@1+ (1,0) [0|1] "" Vector__XXX

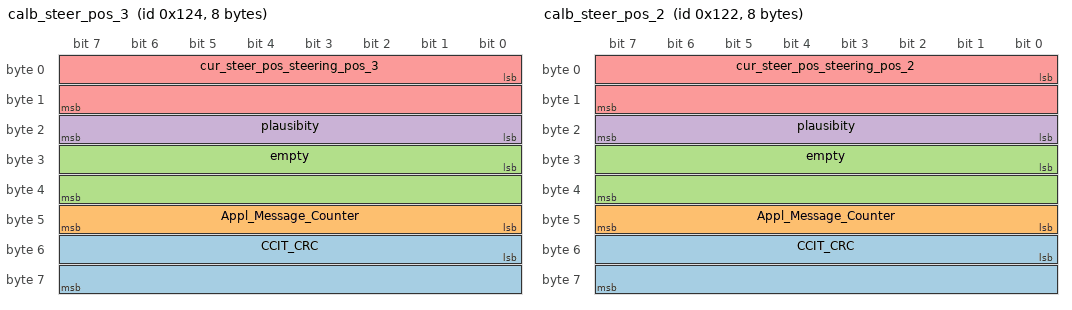
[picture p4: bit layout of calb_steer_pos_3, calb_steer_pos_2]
BO_ 292 calb_steer_pos_3: 8 Vector__XXX
 SG_ CCIT_CRC : 48|16@1+ (1,0) [0|255] "" Vector__XXX
 SG_ Appl_Message_Counter : 40|8@1+ (1,0) [0|255] "" Vector__XXX
 SG_ empty : 24|16@1+ (1,0) [0|65535] "" Vector__XXX
 SG_ plausibity : 16|8@1+ (1,0) [0|255] "" Vector__XXX
 SG_ cur_steer_pos_steering_pos_3 : 0|16@1+ (1,0) [0|65535] "" Vector__XXX

BO_ 290 calb_steer_pos_2: 8 Vector__XXX
 SG_ CCIT_CRC : 48|16@1+ (1,0) [0|255] "" Vector__XXX
 SG_ Appl_Message_Counter : 40|8@1+ (1,0) [0|255] "" Vector__XXX
 SG_ empty : 24|16@1+ (1,0) [0|65535] "" Vector__XXX
 SG_ plausibity : 16|8@1+ (1,0) [0|255] "" Vector__XXX
 SG_ cur_steer_pos_steering_pos_2 : 0|16@1+ (1,0) [0|65535] "" Vector__XXX

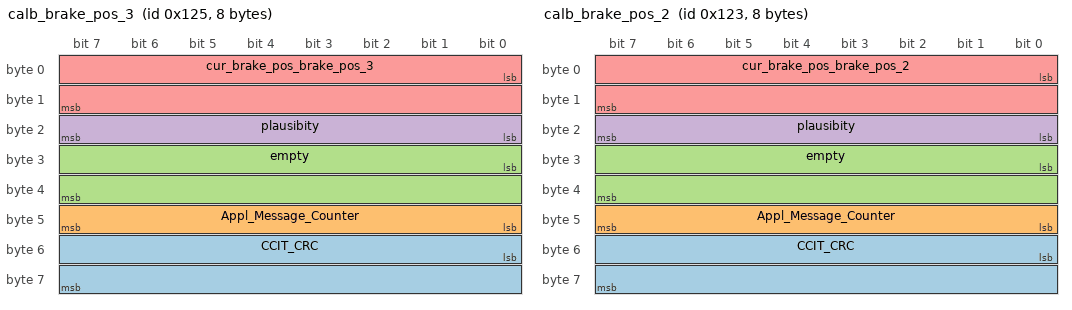
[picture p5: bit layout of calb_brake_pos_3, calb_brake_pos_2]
BO_ 293 calb_brake_pos_3: 8 Vector__XXX
 SG_ CCIT_CRC : 48|16@1+ (1,0) [0|255] "" Vector__XXX
 SG_ Appl_Message_Counter : 40|8@1+ (1,0) [0|255] "" Vector__XXX
 SG_ empty : 24|16@1+ (1,0) [0|65535] "" Vector__XXX
 SG_ plausibity : 16|8@1+ (1,0) [0|255] "" Vector__XXX
 SG_ cur_brake_pos_brake_pos_3 : 0|16@1+ (1,0) [0|65535] "" Vector__XXX

BO_ 291 calb_brake_pos_2: 8 Vector__XXX
 SG_ CCIT_CRC : 48|16@1+ (1,0) [0|255] "" Vector__XXX
 SG_ Appl_Message_Counter : 40|8@1+ (1,0) [0|255] "" Vector__XXX
 SG_ empty : 24|16@1+ (1,0) [0|65535] "" Vector__XXX
 SG_ plausibity : 16|8@1+ (1,0) [0|255] "" Vector__XXX
 SG_ cur_brake_pos_brake_pos_2 : 0|16@1+ (1,0) [0|65535] "" Vector__XXX

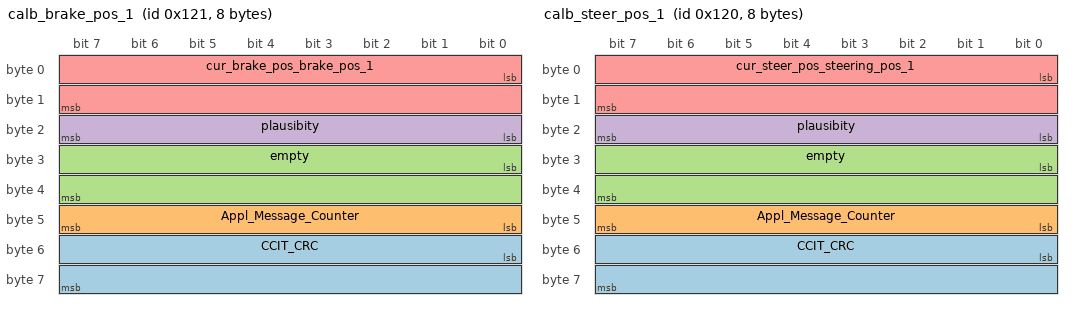
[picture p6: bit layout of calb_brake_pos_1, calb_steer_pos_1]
BO_ 289 calb_brake_pos_1: 8 Vector__XXX
 SG_ CCIT_CRC : 48|16@1+ (1,0) [0|255] "" Vector__XXX
 SG_ Appl_Message_Counter : 40|8@1+ (1,0) [0|255] "" Vector__XXX
 SG_ empty : 24|16@1+ (1,0) [0|65535] "" Vector__XXX
 SG_ plausibity : 16|8@1+ (1,0) [0|255] "" Vector__XXX
 SG_ cur_brake_pos_brake_pos_1 : 0|16@1+ (1,0) [0|65535] "" Vector__XXX

BO_ 288 calb_steer_pos_1: 8 Vector__XXX
 SG_ CCIT_CRC : 48|16@1+ (1,0) [0|255] "" Vector__XXX
 SG_ Appl_Message_Counter : 40|8@1+ (1,0) [0|255] "" Vector__XXX
 SG_ empty : 24|16@1+ (1,0) [0|65535] "" Vector__XXX
 SG_ plausibity : 16|8@1+ (1,0) [0|255] "" Vector__XXX
 SG_ cur_steer_pos_steering_pos_1 : 0|16@1+ (1,0) [0|65535] "" Vector__XXX

BO_ 2314732033 speed_over_ground_novatel: 8 Vector__XXX
 SG_ SOG_Novatel : 32|16@1+ (0.01,0) [0|0] "m/s" Vector__XXX

CM_ BO_ 3221225472 "This is a message for not used signals, created by Vector CANdb++ DBC OLE DB Provider.";
CM_ SG_ 33 CCIT_CRC "CCIT_CRC";
CM_ SG_ 33 Appl_Message_Counter "Appl Message Counter";
CM_ SG_ 33 deactv_joystk_GB "DeaktivateJoystickGB
0 = Release of joystick control is not allowed.
1 = Release of joystick control is allowed";
CM_ SG_ 33 actv_joystk_GB "ActivateJoystickGB
0 = Vehicle take over with joystick is not allowed.
1 = Vehicle take over with joystick is allowed";
CM_ SG_ 33 contrl_pos_brk "control-position  Gas/Brake
range [0x000, 0x8000]
0x0000 = brake end stop 
0x4000 = neutral position 
0x8000 = throttle end stop 
0xFFFF = SNV (Signal Not Valid)
";
CM_ BO_ 32 "RequestedSteeringPosition ";
CM_ SG_ 32 CCIT_CRC "CCIT_CRC";
CM_ SG_ 32 Appl_Message_counter "Appl  Message Counter";
CM_ SG_ 32 deactv_joystk_steer "DeaktivateJoystickStr
0 = Release of joystick control is not allowed.
1 = Release of joystick control is allowed.
";
CM_ SG_ 32 actv_joystk_steer "ActivateJoystickStr
0 = Vehicle take over with joystick is not allowed.
1 = Vehicle take over with joystick is allowed.
";
CM_ SG_ 32 veh_speed "Current Vehicle Speed";
CM_ SG_ 32 cntrl_pos "Control_Position
Requested position for steering
";
CM_ BO_ 133 "StatusBrake";
CM_ SG_ 133 curr_ip_dvc_pos "Current input device position (0000h – 8000h)";
CM_ SG_ 133 bkp_batt_curr_vol_val "Backup Battery current voltage value";
CM_ SG_ 133 main_batt_curr_volt_val "Main Battery current voltage value";
CM_ SG_ 133 gas_crtlr_actv "Gas Controller active";
CM_ SG_ 133 brk_crtlr_actv "Brake Controller active";
CM_ SG_ 133 joystk_actv "Joystick active [digital IN]";
CM_ SG_ 133 emr_brk "Emergency brake";
CM_ SG_ 133 lo_brk "Low brake";
CM_ SG_ 133 warn_ton_actv "Warning tone active  ";
CM_ SG_ 133 err_led_act "Error LED active";
CM_ SG_ 133 ip_sgnl_vald "Input signal valid";
CM_ SG_ 133 Ign_actv "Ignition active";
CM_ SG_ 133 strt_initial "Start initialization";
CM_ BO_ 131 "StatusBrake";
CM_ SG_ 131 curr_ip_dvc_pos "Current input device position (0000h – 8000h)";
CM_ SG_ 131 bkp_batt_curr_vol_val "Backup Battery current voltage value";
CM_ SG_ 131 main_batt_curr_volt_val "Main Battery current voltage value";
CM_ SG_ 131 gas_crtlr_actv "Gas Controller active";
CM_ SG_ 131 brk_crtlr_actv "Brake Controller active";
CM_ SG_ 131 joystk_actv "Joystick active [digital IN]";
CM_ SG_ 131 emr_brk "Emergency brake";
CM_ SG_ 131 lo_brk "Low brake";
CM_ SG_ 131 warn_ton_actv "Warning tone active  ";
CM_ SG_ 131 err_led_act "Error LED active";
CM_ SG_ 131 ip_sgnl_vald "Input signal valid";
CM_ SG_ 131 Ign_actv "Ignition active";
CM_ SG_ 131 strt_initial "Start initialization";
CM_ BO_ 129 "StatusBrake";
CM_ SG_ 129 curr_ip_dvc_pos "Current input device position (0000h – 8000h)";
CM_ SG_ 129 bkp_batt_curr_vol_val "Backup Battery current voltage value";
CM_ SG_ 129 main_batt_curr_volt_val "Main Battery current voltage value";
CM_ SG_ 129 gas_crtlr_actv "Gas Controller active";
CM_ SG_ 129 brk_crtlr_actv "Brake Controller active";
CM_ SG_ 129 joystk_actv "Joystick active [digital IN]";
CM_ SG_ 129 emr_brk "Emergency brake";
CM_ SG_ 129 lo_brk "Low brake";
CM_ SG_ 129 warn_ton_actv "Warning tone active  ";
CM_ SG_ 129 err_led_act "Error LED active";
CM_ SG_ 129 ip_sgnl_vald "Input signal valid";
CM_ SG_ 129 Ign_actv "Ignition active";
CM_ SG_ 129 strt_initial "Start initialization";
CM_ BO_ 132 "StatusSteering";
CM_ SG_ 132 rsrvd_3 "reserved";
CM_ SG_ 132 rsrvd_2 "reserved";
CM_ SG_ 132 rsrvd_1 "reserved";
CM_ SG_ 132 joystk_actv "Joystick active [digital IN]";
CM_ SG_ 132 veh_in_motn "Set when vehicle is in motion ";
CM_ SG_ 132 brk_lit_actv "Brake light, bit is set when brake light is active. ";
CM_ SG_ 132 emr_brk "Emergency brake";
CM_ SG_ 132 lo_brk "Low brake";
CM_ SG_ 132 warn_ton_actv "Warning tone active  ";
CM_ SG_ 132 err_led_act "Error LED active";
CM_ SG_ 132 str_ctrl_act "Steering controller active";
CM_ SG_ 132 spd_depnd_str_dsbld "Speed depending steering is disabled";
CM_ SG_ 132 ip_sgnl_vald "Input signal valid";
CM_ SG_ 132 Ign_actv "Ignition active";
CM_ SG_ 132 strt_initial "Start initialization";
CM_ BO_ 130 "StatusSteering";
CM_ SG_ 130 rsrvd_3 "reserved";
CM_ SG_ 130 rsrvd_2 "reserved";
CM_ SG_ 130 rsrvd_1 "reserved";
CM_ SG_ 130 joystk_actv "Joystick active [digital IN]";
CM_ SG_ 130 veh_in_motn "Set when vehicle is in motion ";
CM_ SG_ 130 brk_lit_actv "Brake light, bit is set when brake light is active. ";
CM_ SG_ 130 emr_brk "Emergency brake";
CM_ SG_ 130 lo_brk "Low brake";
CM_ SG_ 130 warn_ton_actv "Warning tone active  ";
CM_ SG_ 130 err_led_act "Error LED active";
CM_ SG_ 130 str_ctrl_act "Steering controller active";
CM_ SG_ 130 spd_depnd_str_dsbld "Speed depending steering is disabled";
CM_ SG_ 130 ip_sgnl_vald "Input signal valid";
CM_ SG_ 130 Ign_actv "Ignition active";
CM_ SG_ 130 strt_initial "Start initialization";
CM_ BO_ 128 "StatusSteering";
CM_ SG_ 128 rsrvd_3 "reserved";
CM_ SG_ 128 rsrvd_2 "reserved";
CM_ SG_ 128 rsrvd_1 "reserved";
CM_ SG_ 128 joystk_actv "Joystick active [digital IN]";
CM_ SG_ 128 veh_in_motn "Set when vehicle is in motion ";
CM_ SG_ 128 brk_lit_actv "Brake light, bit is set when brake light is active. ";
CM_ SG_ 128 emr_brk "Emergency brake";
CM_ SG_ 128 lo_brk "Low brake";
CM_ SG_ 128 warn_ton_actv "Warning tone active  ";
CM_ SG_ 128 err_led_act "Error LED active";
CM_ SG_ 128 str_ctrl_act "Steering controller active";
CM_ SG_ 128 spd_depnd_str_dsbld "Speed depending steering is disabled";
CM_ SG_ 128 ip_sgnl_vald "Input signal valid";
CM_ SG_ 128 Ign_actv "Ignition active";
CM_ SG_ 128 strt_initial "Start initialization";
CM_ BO_ 101 "ActiveErrorBraking";
CM_ SG_ 101 crtcl_err_recognzd "Critical error recognized";
CM_ SG_ 101 err_CAN_2 "Error CAN 2";
CM_ SG_ 101 err_CAN_1 "Error CAN 1";
CM_ SG_ 101 ovrld_mtr_pwr "Overload motor power";
CM_ SG_ 101 runtm_err "Runtime error";
CM_ SG_ 101 err_memo_100_pcnt_full "Error memory 100% full";
CM_ SG_ 101 err_memo_80_pcnt_full "Error memory 80% full";
CM_ SG_ 101 ctrlr_temp_to_hi "Controller temperature to high";
CM_ SG_ 101 psn_sen_srv_mtr_implausible "Position sensor servo motors implausible";
CM_ SG_ 101 RESET_whl_optg "RESET while operating";
CM_ SG_ 101 err_ctrl_val_2 "Error control value 2";
CM_ SG_ 101 err_ctrl_val_1 "Error control value 1";
CM_ SG_ 101 err_ngv_voltg_pwr_supp_3 "Error negative voltage power supply 3";
CM_ SG_ 101 err_ngv_voltg_pwr_supp_2 "Error negative voltage power supply 2";
CM_ SG_ 101 err_ngv_voltg_pwr_supp_1 "Error negative voltage power supply 1";
CM_ SG_ 101 err_3p3V_pwr_supp_2 "Error  3.3V power supply 2";
CM_ SG_ 101 err_3p3V_pwr_supp_1 "Error  3.3V power supply 1";
CM_ SG_ 101 err_5V_pwr_supp_3 "Error  5V power supply 3";
CM_ SG_ 101 err_5V_pwr_supp_2 "Error  5V power supply 2";
CM_ SG_ 101 err_5V_pwr_supp_1 "Error  5V power supply 1  ";
CM_ SG_ 101 H_brdg_3_fail "H-bridge 3 failure";
CM_ SG_ 101 H_brdg_2_fail "H-bridge 2 failure";
CM_ SG_ 101 H_brdg_1_fail "H-bridge 1 failure";
CM_ SG_ 101 err_srv_mtr_pos_sen_3 "error servo motor   position sensor 3";
CM_ SG_ 101 err_srv_mtr_2_STR_pwr_drn "Error servo motor2 STR, power drain ";
CM_ SG_ 101 err_srv_mtr_1_STR_pwr_drn "Error servo motor1 STR, power drain ";
CM_ SG_ 101 RAM_Chk_fail "RAM Check failure";
CM_ SG_ 101 flsh_CRC_fail "Flash CRC Failure";
CM_ SG_ 101 Ctrlr_temp_crit_low "Controller temperature critical low";
CM_ SG_ 101 Ctrlr_temp_crit_hi "Controller temperature critical high";
CM_ SG_ 101 err_srv_mtr_2_GB_pwr_drn "Error servo motor2 GB, power drain ";
CM_ SG_ 101 err_srv_mtr_1_GB_pwr_drn "Error servo motor1 GB, power drain ";
CM_ SG_ 101 Vol_bkp_batt_lo "Voltage backup battery to low";
CM_ SG_ 101 Vol_bkp_batt_hi "Voltage backup battery to high";
CM_ SG_ 101 Vol_main_batt_lo "Voltage main battery to low";
CM_ SG_ 101 Vol_main_batt_hi "Voltage main battery to high";
CM_ SG_ 101 err_srv_mtr_pos_sen_2 "error servo motor   position sensor 2";
CM_ SG_ 101 err_srv_mtr_pos_sen_1 "error servo motor   position sensor 1";
CM_ SG_ 101 ip_dvc_err_sen_3 "Input device error sensor3";
CM_ SG_ 101 ip_dvc_err_sen_2 "Input device error sensor2";
CM_ SG_ 101 ip_dvc_err_sen_1 "Input device error sensor1";
CM_ BO_ 99 "ActiveErrorBraking";
CM_ SG_ 99 crtcl_err_recognzd "Critical error recognized";
CM_ SG_ 99 err_CAN_2 "Error CAN 2";
CM_ SG_ 99 err_CAN_1 "Error CAN 1";
CM_ SG_ 99 ovrld_mtr_pwr "Overload motor power";
CM_ SG_ 99 runtm_err "Runtime error";
CM_ SG_ 99 err_memo_100_pcnt_full "Error memory 100% full";
CM_ SG_ 99 err_memo_80_pcnt_full "Error memory 80% full";
CM_ SG_ 99 ctrlr_temp_to_hi "Controller temperature to high";
CM_ SG_ 99 psn_sen_srv_mtr_implausible "Position sensor servo motors implausible";
CM_ SG_ 99 RESET_whl_optg "RESET while operating";
CM_ SG_ 99 err_ctrl_val_2 "Error control value 2";
CM_ SG_ 99 err_ctrl_val_1 "Error control value 1";
CM_ SG_ 99 err_ngv_voltg_pwr_supp_3 "Error negative voltage power supply 3";
CM_ SG_ 99 err_ngv_voltg_pwr_supp_2 "Error negative voltage power supply 2";
CM_ SG_ 99 err_ngv_voltg_pwr_supp_1 "Error negative voltage power supply 1";
CM_ SG_ 99 err_3p3V_pwr_supp_2 "Error  3.3V power supply 2";
CM_ SG_ 99 err_3p3V_pwr_supp_1 "Error  3.3V power supply 1";
CM_ SG_ 99 err_5V_pwr_supp_3 "Error  5V power supply 3";
CM_ SG_ 99 err_5V_pwr_supp_2 "Error  5V power supply 2";
CM_ SG_ 99 err_5V_pwr_supp_1 "Error  5V power supply 1  ";
CM_ SG_ 99 H_brdg_3_fail "H-bridge 3 failure";
CM_ SG_ 99 H_brdg_2_fail "H-bridge 2 failure";
CM_ SG_ 99 H_brdg_1_fail "H-bridge 1 failure";
CM_ SG_ 99 err_srv_mtr_pos_sen_3 "error servo motor   position sensor 3";
CM_ SG_ 99 err_srv_mtr_2_STR_pwr_drn "Error servo motor2 STR, power drain ";
CM_ SG_ 99 err_srv_mtr_1_STR_pwr_drn "Error servo motor1 STR, power drain ";
CM_ SG_ 99 RAM_Chk_fail "RAM Check failure";
CM_ SG_ 99 flsh_CRC_fail "Flash CRC Failure";
CM_ SG_ 99 Ctrlr_temp_crit_low "Controller temperature critical low";
CM_ SG_ 99 Ctrlr_temp_crit_hi "Controller temperature critical high";
CM_ SG_ 99 err_srv_mtr_2_GB_pwr_drn "Error servo motor2 GB, power drain ";
CM_ SG_ 99 err_srv_mtr_1_GB_pwr_drn "Error servo motor1 GB, power drain ";
CM_ SG_ 99 Vol_bkp_batt_lo "Voltage backup battery to low";
CM_ SG_ 99 Vol_bkp_batt_hi "Voltage backup battery to high";
CM_ SG_ 99 Vol_main_batt_lo "Voltage main battery to low";
CM_ SG_ 99 Vol_main_batt_hi "Voltage main battery to high";
CM_ SG_ 99 err_srv_mtr_pos_sen_2 "error servo motor   position sensor 2";
CM_ SG_ 99 err_srv_mtr_pos_sen_1 "error servo motor   position sensor 1";
CM_ SG_ 99 ip_dvc_err_sen_3 "Input device error sensor3";
CM_ SG_ 99 ip_dvc_err_sen_2 "Input device error sensor2";
CM_ SG_ 99 ip_dvc_err_sen_1 "Input device error sensor1";
CM_ BO_ 100 "ActiveErrorSteering";
CM_ SG_ 100 crtcl_err_recognzd "Critical error recognized";
CM_ SG_ 100 err_CAN_2 "Error CAN 2";
CM_ SG_ 100 err_CAN_1 "Error CAN 1";
CM_ SG_ 100 ovrld_mtr_pwr "Overload motor power";
CM_ SG_ 100 runtm_err "Runtime error";
CM_ SG_ 100 err_memo_100_pcnt_full "Error memory 100% full";
CM_ SG_ 100 err_memo_80_pcnt_full "Error memory 80% full";
CM_ SG_ 100 ctrlr_temp_to_hi "Controller temperature to high";
CM_ SG_ 100 psn_sen_srv_mtr_implausible "Position sensor servo motors implausible";
CM_ SG_ 100 RESET_whl_optg "RESET while operating";
CM_ SG_ 100 err_ctrl_val_2 "Error control value 2";
CM_ SG_ 100 err_ctrl_val_1 "Error control value 1";
CM_ SG_ 100 err_ngv_voltg_pwr_supp_3 "Error negative voltage power supply 3";
CM_ SG_ 100 err_ngv_voltg_pwr_supp_2 "Error negative voltage power supply 2";
CM_ SG_ 100 err_ngv_voltg_pwr_supp_1 "Error negative voltage power supply 1";
CM_ SG_ 100 err_3p3V_pwr_supp_2 "Error  3.3V power supply 2";
CM_ SG_ 100 err_3p3V_pwr_supp_1 "Error  3.3V power supply 1";
CM_ SG_ 100 err_5V_pwr_supp_3 "Error  5V power supply 3";
CM_ SG_ 100 err_5V_pwr_supp_2 "Error  5V power supply 2";
CM_ SG_ 100 err_5V_pwr_supp_1 "Error  5V power supply 1  ";
CM_ SG_ 100 H_brdg_3_fail "H-bridge 3 failure";
CM_ SG_ 100 H_brdg_2_fail "H-bridge 2 failure";
CM_ SG_ 100 H_brdg_1_fail "H-bridge 1 failure";
CM_ SG_ 100 err_srv_mtr_pos_sen_3 "error servo motor   position sensor 3";
CM_ SG_ 100 err_srv_mtr_2_STR_pwr_drn "Error servo motor2 STR, power drain ";
CM_ SG_ 100 err_srv_mtr_1_STR_pwr_drn "Error servo motor1 STR, power drain ";
CM_ SG_ 100 RAM_Chk_fail "RAM Check failure";
CM_ SG_ 100 flsh_CRC_fail "Flash CRC Failure";
CM_ SG_ 100 Ctrlr_temp_crit_low "Controller temperature critical low";
CM_ SG_ 100 Ctrlr_temp_crit_hi "Controller temperature critical high";
CM_ SG_ 100 err_srv_mtr_2_GB_pwr_drn "Error servo motor2 GB, power drain ";
CM_ SG_ 100 err_srv_mtr_1_GB_pwr_drn "Error servo motor1 GB, power drain ";
CM_ SG_ 100 Vol_bkp_batt_lo "Voltage backup battery to low";
CM_ SG_ 100 Vol_bkp_batt_hi "Voltage backup battery to high";
CM_ SG_ 100 Vol_main_batt_lo "Voltage main battery to low";
CM_ SG_ 100 Vol_main_batt_hi "Voltage main battery to high";
CM_ SG_ 100 err_srv_mtr_pos_sen_2 "error servo motor   position sensor 2";
CM_ SG_ 100 err_srv_mtr_pos_sen_1 "error servo motor   position sensor 1";
CM_ SG_ 100 ip_dvc_err_sen_3 "Input device error sensor3";
CM_ SG_ 100 ip_dvc_err_sen_2 "Input device error sensor2";
CM_ SG_ 100 ip_dvc_err_sen_1 "Input device error sensor1";
CM_ BO_ 98 "ActiveErrorSteering";
CM_ SG_ 98 crtcl_err_recognzd "Critical error recognized";
CM_ SG_ 98 err_CAN_2 "Error CAN 2";
CM_ SG_ 98 err_CAN_1 "Error CAN 1";
CM_ SG_ 98 ovrld_mtr_pwr "Overload motor power";
CM_ SG_ 98 runtm_err "Runtime error";
CM_ SG_ 98 err_memo_100_pcnt_full "Error memory 100% full";
CM_ SG_ 98 err_memo_80_pcnt_full "Error memory 80% full";
CM_ SG_ 98 ctrlr_temp_to_hi "Controller temperature to high";
CM_ SG_ 98 psn_sen_srv_mtr_implausible "Position sensor servo motors implausible";
CM_ SG_ 98 RESET_whl_optg "RESET while operating";
CM_ SG_ 98 err_ctrl_val_2 "Error control value 2";
CM_ SG_ 98 err_ctrl_val_1 "Error control value 1";
CM_ SG_ 98 err_ngv_voltg_pwr_supp_3 "Error negative voltage power supply 3";
CM_ SG_ 98 err_ngv_voltg_pwr_supp_2 "Error negative voltage power supply 2";
CM_ SG_ 98 err_ngv_voltg_pwr_supp_1 "Error negative voltage power supply 1";
CM_ SG_ 98 err_3p3V_pwr_supp_2 "Error  3.3V power supply 2";
CM_ SG_ 98 err_3p3V_pwr_supp_1 "Error  3.3V power supply 1";
CM_ SG_ 98 err_5V_pwr_supp_3 "Error  5V power supply 3";
CM_ SG_ 98 err_5V_pwr_supp_2 "Error  5V power supply 2";
CM_ SG_ 98 err_5V_pwr_supp_1 "Error  5V power supply 1  ";
CM_ SG_ 98 H_brdg_3_fail "H-bridge 3 failure";
CM_ SG_ 98 H_brdg_2_fail "H-bridge 2 failure";
CM_ SG_ 98 H_brdg_1_fail "H-bridge 1 failure";
CM_ SG_ 98 err_srv_mtr_pos_sen_3 "error servo motor   position sensor 3";
CM_ SG_ 98 err_srv_mtr_2_STR_pwr_drn "Error servo motor2 STR, power drain ";
CM_ SG_ 98 err_srv_mtr_1_STR_pwr_drn "Error servo motor1 STR, power drain ";
CM_ SG_ 98 RAM_Chk_fail "RAM Check failure";
CM_ SG_ 98 flsh_CRC_fail "Flash CRC Failure";
CM_ SG_ 98 Ctrlr_temp_crit_low "Controller temperature critical low";
CM_ SG_ 98 Ctrlr_temp_crit_hi "Controller temperature critical high";
CM_ SG_ 98 err_srv_mtr_2_GB_pwr_drn "Error servo motor2 GB, power drain ";
CM_ SG_ 98 err_srv_mtr_1_GB_pwr_drn "Error servo motor1 GB, power drain ";
CM_ SG_ 98 Vol_bkp_batt_lo "Voltage backup battery to low";
CM_ SG_ 98 Vol_bkp_batt_hi "Voltage backup battery to high";
CM_ SG_ 98 Vol_main_batt_lo "Voltage main battery to low";
CM_ SG_ 98 Vol_main_batt_hi "Voltage main battery to high";
CM_ SG_ 98 err_srv_mtr_pos_sen_2 "error servo motor   position sensor 2";
CM_ SG_ 98 err_srv_mtr_pos_sen_1 "error servo motor   position sensor 1";
CM_ SG_ 98 ip_dvc_err_sen_3 "Input device error sensor3";
CM_ SG_ 98 ip_dvc_err_sen_2 "Input device error sensor2";
CM_ SG_ 98 ip_dvc_err_sen_1 "Input device error sensor1";
CM_ BO_ 97 "ActiveErrorBraking";
CM_ SG_ 97 crtcl_err_recognzd "Critical error recognized";
CM_ SG_ 97 err_CAN_2 "Error CAN 2";
CM_ SG_ 97 err_CAN_1 "Error CAN 1";
CM_ SG_ 97 ovrld_mtr_pwr "Overload motor power";
CM_ SG_ 97 runtm_err "Runtime error";
CM_ SG_ 97 err_memo_100_pcnt_full "Error memory 100% full";
CM_ SG_ 97 err_memo_80_pcnt_full "Error memory 80% full";
CM_ SG_ 97 ctrlr_temp_to_hi "Controller temperature to high";
CM_ SG_ 97 psn_sen_srv_mtr_implausible "Position sensor servo motors implausible";
CM_ SG_ 97 RESET_whl_optg "RESET while operating";
CM_ SG_ 97 err_ctrl_val_2 "Error control value 2";
CM_ SG_ 97 err_ctrl_val_1 "Error control value 1";
CM_ SG_ 97 err_ngv_voltg_pwr_supp_3 "Error negative voltage power supply 3";
CM_ SG_ 97 err_ngv_voltg_pwr_supp_2 "Error negative voltage power supply 2";
CM_ SG_ 97 err_ngv_voltg_pwr_supp_1 "Error negative voltage power supply 1";
CM_ SG_ 97 err_3p3V_pwr_supp_2 "Error  3.3V power supply 2";
CM_ SG_ 97 err_3p3V_pwr_supp_1 "Error  3.3V power supply 1";
CM_ SG_ 97 err_5V_pwr_supp_3 "Error  5V power supply 3";
CM_ SG_ 97 err_5V_pwr_supp_2 "Error  5V power supply 2";
CM_ SG_ 97 err_5V_pwr_supp_1 "Error  5V power supply 1  ";
CM_ SG_ 97 H_brdg_3_fail "H-bridge 3 failure";
CM_ SG_ 97 H_brdg_2_fail "H-bridge 2 failure";
CM_ SG_ 97 H_brdg_1_fail "H-bridge 1 failure";
CM_ SG_ 97 err_srv_mtr_pos_sen_3 "error servo motor   position sensor 3";
CM_ SG_ 97 err_srv_mtr_2_STR_pwr_drn "Error servo motor2 STR, power drain ";
CM_ SG_ 97 err_srv_mtr_1_STR_pwr_drn "Error servo motor1 STR, power drain ";
CM_ SG_ 97 RAM_Chk_fail "RAM Check failure";
CM_ SG_ 97 flsh_CRC_fail "Flash CRC Failure";
CM_ SG_ 97 Ctrlr_temp_crit_low "Controller temperature critical low";
CM_ SG_ 97 Ctrlr_temp_crit_hi "Controller temperature critical high";
CM_ SG_ 97 err_srv_mtr_2_GB_pwr_drn "Error servo motor2 GB, power drain ";
CM_ SG_ 97 err_srv_mtr_1_GB_pwr_drn "Error servo motor1 GB, power drain ";
CM_ SG_ 97 Vol_bkp_batt_lo "Voltage backup battery to low";
CM_ SG_ 97 Vol_bkp_batt_hi "Voltage backup battery to high";
CM_ SG_ 97 Vol_main_batt_lo "Voltage main battery to low";
CM_ SG_ 97 Vol_main_batt_hi "Voltage main battery to high";
CM_ SG_ 97 err_srv_mtr_pos_sen_2 "error servo motor   position sensor 2";
CM_ SG_ 97 err_srv_mtr_pos_sen_1 "error servo motor   position sensor 1";
CM_ SG_ 97 ip_dvc_err_sen_3 "Input device error sensor3";
CM_ SG_ 97 ip_dvc_err_sen_2 "Input device error sensor2";
CM_ SG_ 97 ip_dvc_err_sen_1 "Input device error sensor1";
CM_ BO_ 96 "ActiveErrorSteering";
CM_ SG_ 96 crtcl_err_recognzd "Critical error recognized";
CM_ SG_ 96 err_CAN_2 "Error CAN 2";
CM_ SG_ 96 err_CAN_1 "Error CAN 1";
CM_ SG_ 96 ovrld_mtr_pwr "Overload motor power";
CM_ SG_ 96 runtm_err "Runtime error";
CM_ SG_ 96 err_memo_100_pcnt_full "Error memory 100% full";
CM_ SG_ 96 err_memo_80_pcnt_full "Error memory 80% full";
CM_ SG_ 96 ctrlr_temp_to_hi "Controller temperature to high";
CM_ SG_ 96 psn_sen_srv_mtr_implausible "Position sensor servo motors implausible";
CM_ SG_ 96 RESET_whl_optg "RESET while operating";
CM_ SG_ 96 err_ctrl_val_2 "Error control value 2";
CM_ SG_ 96 err_ctrl_val_1 "Error control value 1";
CM_ SG_ 96 err_ngv_voltg_pwr_supp_3 "Error negative voltage power supply 3";
CM_ SG_ 96 err_ngv_voltg_pwr_supp_2 "Error negative voltage power supply 2";
CM_ SG_ 96 err_ngv_voltg_pwr_supp_1 "Error negative voltage power supply 1";
CM_ SG_ 96 err_3p3V_pwr_supp_2 "Error  3.3V power supply 2";
CM_ SG_ 96 err_3p3V_pwr_supp_1 "Error  3.3V power supply 1";
CM_ SG_ 96 err_5V_pwr_supp_3 "Error  5V power supply 3";
CM_ SG_ 96 err_5V_pwr_supp_2 "Error  5V power supply 2";
CM_ SG_ 96 err_5V_pwr_supp_1 "Error  5V power supply 1  ";
CM_ SG_ 96 H_brdg_3_fail "H-bridge 3 failure";
CM_ SG_ 96 H_brdg_2_fail "H-bridge 2 failure";
CM_ SG_ 96 H_brdg_1_fail "H-bridge 1 failure";
CM_ SG_ 96 err_srv_mtr_pos_sen_3 "error servo motor   position sensor 3";
CM_ SG_ 96 err_srv_mtr_2_STR_pwr_drn "Error servo motor2 STR, power drain ";
CM_ SG_ 96 err_srv_mtr_1_STR_pwr_drn "Error servo motor1 STR, power drain ";
CM_ SG_ 96 RAM_Chk_fail "RAM Check failure";
CM_ SG_ 96 flsh_CRC_fail "Flash CRC Failure";
CM_ SG_ 96 Ctrlr_temp_crit_low "Controller temperature critical low";
CM_ SG_ 96 Ctrlr_temp_crit_hi "Controller temperature critical high";
CM_ SG_ 96 err_srv_mtr_2_GB_pwr_drn "Error servo motor2 GB, power drain ";
CM_ SG_ 96 err_srv_mtr_1_GB_pwr_drn "Error servo motor1 GB, power drain ";
CM_ SG_ 96 Vol_bkp_batt_lo "Voltage backup battery to low";
CM_ SG_ 96 Vol_bkp_batt_hi "Voltage backup battery to high";
CM_ SG_ 96 Vol_main_batt_lo "Voltage main battery to low";
CM_ SG_ 96 Vol_main_batt_hi "Voltage main battery to high";
CM_ SG_ 96 err_srv_mtr_pos_sen_2 "error servo motor   position sensor 2";
CM_ SG_ 96 err_srv_mtr_pos_sen_1 "error servo motor   position sensor 1";
CM_ SG_ 96 ip_dvc_err_sen_3 "Input device error sensor3";
CM_ SG_ 96 ip_dvc_err_sen_2 "Input device error sensor2";
CM_ SG_ 96 ip_dvc_err_sen_1 "Input device error sensor1";
CM_ BO_ 292 "Calibrated position of the steering";
CM_ SG_ 292 CCIT_CRC "Safety relevant

CRC checksum CCITT16";
CM_ SG_ 292 Appl_Message_Counter "Safety Relevant

Message counter ";
CM_ SG_ 292 empty "0";
CM_ SG_ 292 plausibity "0: Position values are plausible
2: Position is not plausible
";
CM_ SG_ 292 cur_steer_pos_steering_pos_3 "Arbitrated current position of the steering motor
0x0000 = full brake
0x4000 = neutral
0x8000 = full acc
0xFFFF = SNV (Signal Not Valid)
";
CM_ BO_ 290 "Calibrated position of the steering";
CM_ SG_ 290 CCIT_CRC "Safety relevant

CRC checksum CCITT16";
CM_ SG_ 290 Appl_Message_Counter "Safety Relevant

Message counter ";
CM_ SG_ 290 empty "0";
CM_ SG_ 290 plausibity "0: Position values are plausible
2: Position is not plausible
";
CM_ SG_ 290 cur_steer_pos_steering_pos_2 "Arbitrated current position of the steering motor
0x0000 = full brake
0x4000 = neutral
0x8000 = full acc
0xFFFF = SNV (Signal Not Valid)
";
CM_ BO_ 293 "Calibrated position of the steering";
CM_ SG_ 293 CCIT_CRC "Safety relevant

CRC checksum CCITT16";
CM_ SG_ 293 Appl_Message_Counter "Safety Relevant

Message counter ";
CM_ SG_ 293 empty "0";
CM_ SG_ 293 plausibity "0: Position values are plausible
2: Position is not plausible
";
CM_ SG_ 293 cur_brake_pos_brake_pos_3 "Arbitrated current position of the steering motor
0x0000 = full brake
0x4000 = neutral
0x8000 = full acc
0xFFFF = SNV (Signal Not Valid)
";
CM_ BO_ 291 "Calibrated position of the steering";
CM_ SG_ 291 CCIT_CRC "Safety relevant

CRC checksum CCITT16";
CM_ SG_ 291 Appl_Message_Counter "Safety Relevant

Message counter ";
CM_ SG_ 291 empty "0";
CM_ SG_ 291 plausibity "0: Position values are plausible
2: Position is not plausible
";
CM_ SG_ 291 cur_brake_pos_brake_pos_2 "Arbitrated current position of the steering motor
0x0000 = full brake
0x4000 = neutral
0x8000 = full acc
0xFFFF = SNV (Signal Not Valid)
";
CM_ BO_ 289 "Calibrated position of the steering";
CM_ SG_ 289 CCIT_CRC "Safety relevant

CRC checksum CCITT16";
CM_ SG_ 289 Appl_Message_Counter "Safety Relevant

Message counter ";
CM_ SG_ 289 empty "0";
CM_ SG_ 289 plausibity "0: Position values are plausible
2: Position is not plausible
";
CM_ SG_ 289 cur_brake_pos_brake_pos_1 "Arbitrated current position of the steering motor
0x0000 = full brake
0x4000 = neutral
0x8000 = full acc
0xFFFF = SNV (Signal Not Valid)
";
CM_ BO_ 288 "Calibrated position of the steering
";
CM_ SG_ 288 CCIT_CRC "Safety relevant

CRC checksum CCITT16";
CM_ SG_ 288 Appl_Message_Counter "Safety Relevant

Message counter ";
CM_ SG_ 288 empty "0";
CM_ SG_ 288 plausibity "0: Position values are plausible
2: Position is not plausible
";
CM_ SG_ 288 cur_steer_pos_steering_pos_1 "Arbitrated current position of the steering motor
0x0000 = full brake
0x4000 = neutral
0x8000 = full acc
0xFFFF = SNV (Signal Not Valid)
";
CM_ BO_ 2314732033 "Added vehicle_speed from Novatel (10.42.X.61)
If you have reset this unit please contact me to enable this message on the unit.
Intent is to provide additional speed source at Raptor for purple flage braking logic";
BA_DEF_  "BusType" STRING ;
BA_DEF_DEF_  "BusType" "CAN";
